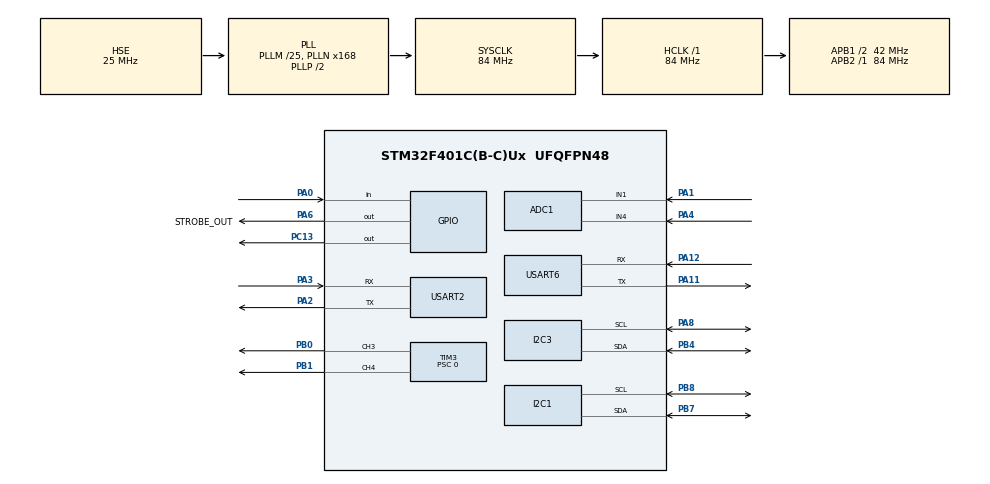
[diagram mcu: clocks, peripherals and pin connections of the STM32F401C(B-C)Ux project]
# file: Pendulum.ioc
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ADC1.Channel-0\#ChannelRegularConversion=ADC_CHANNEL_1
ADC1.Channel-1\#ChannelRegularConversion=ADC_CHANNEL_4
ADC1.ClockPrescaler=ADC_CLOCK_SYNC_PCLK_DIV8
ADC1.ContinuousConvMode=DISABLE
ADC1.DMAContinuousRequests=DISABLE
ADC1.EOCSelection=ADC_EOC_SEQ_CONV
ADC1.ExternalTrigConv=ADC_SOFTWARE_START
ADC1.NbrOfConversion=2
ADC1.NbrOfConversionFlag=1
ADC1.Rank-0\#ChannelRegularConversion=1
ADC1.Rank-1\#ChannelRegularConversion=2
ADC1.SamplingTime-0\#ChannelRegularConversion=ADC_SAMPLETIME_480CYCLES
ADC1.SamplingTime-1\#ChannelRegularConversion=ADC_SAMPLETIME_480CYCLES
ADC1.master=1
Dma.ADC1.3.Direction=DMA_PERIPH_TO_MEMORY
Dma.ADC1.3.FIFOMode=DMA_FIFOMODE_DISABLE
Dma.ADC1.3.Instance=DMA2_Stream0
Dma.ADC1.3.MemDataAlignment=DMA_MDATAALIGN_HALFWORD
Dma.ADC1.3.MemInc=DMA_MINC_ENABLE
Dma.ADC1.3.Mode=DMA_CIRCULAR
Dma.ADC1.3.PeriphDataAlignment=DMA_PDATAALIGN_HALFWORD
Dma.ADC1.3.PeriphInc=DMA_PINC_DISABLE
Dma.ADC1.3.Priority=DMA_PRIORITY_MEDIUM
Dma.I2C3_TX.0.Direction=DMA_MEMORY_TO_PERIPH
Dma.I2C3_TX.0.FIFOMode=DMA_FIFOMODE_ENABLE
Dma.I2C3_TX.0.FIFOThreshold=DMA_FIFO_THRESHOLD_FULL
Dma.I2C3_TX.0.Instance=DMA1_Stream4
Dma.I2C3_TX.0.MemBurst=DMA_MBURST_SINGLE
Dma.I2C3_TX.0.MemDataAlignment=DMA_MDATAALIGN_BYTE
Dma.I2C3_TX.0.MemInc=DMA_MINC_ENABLE
Dma.I2C3_TX.0.Mode=DMA_NORMAL
Dma.I2C3_TX.0.PeriphBurst=DMA_PBURST_SINGLE
Dma.I2C3_TX.0.PeriphDataAlignment=DMA_PDATAALIGN_BYTE
Dma.I2C3_TX.0.PeriphInc=DMA_PINC_DISABLE
Dma.I2C3_TX.0.Priority=DMA_PRIORITY_HIGH
Dma.Request0=I2C3_TX
Dma.Request1=TIM3_CH3
Dma.Request2=TIM3_CH4/UP
Dma.Request3=ADC1
Dma.TIM3_CH3.1.Direction=DMA_MEMORY_TO_PERIPH
Dma.TIM3_CH3.1.FIFOMode=DMA_FIFOMODE_ENABLE
Dma.TIM3_CH3.1.FIFOThreshold=DMA_FIFO_THRESHOLD_FULL
Dma.TIM3_CH3.1.Instance=DMA1_Stream7
Dma.TIM3_CH3.1.MemBurst=DMA_MBURST_SINGLE
Dma.TIM3_CH3.1.MemDataAlignment=DMA_MDATAALIGN_WORD
Dma.TIM3_CH3.1.MemInc=DMA_MINC_ENABLE
Dma.TIM3_CH3.1.Mode=DMA_NORMAL
Dma.TIM3_CH3.1.PeriphBurst=DMA_PBURST_SINGLE
Dma.TIM3_CH3.1.PeriphDataAlignment=DMA_PDATAALIGN_WORD
Dma.TIM3_CH3.1.PeriphInc=DMA_PINC_DISABLE
Dma.TIM3_CH3.1.Priority=DMA_PRIORITY_HIGH
Dma.TIM3_CH4/UP.2.Direction=DMA_MEMORY_TO_PERIPH
Dma.TIM3_CH4/UP.2.FIFOMode=DMA_FIFOMODE_ENABLE
Dma.TIM3_CH4/UP.2.FIFOThreshold=DMA_FIFO_THRESHOLD_FULL
Dma.TIM3_CH4/UP.2.Instance=DMA1_Stream2
Dma.TIM3_CH4/UP.2.MemBurst=DMA_MBURST_SINGLE
Dma.TIM3_CH4/UP.2.MemDataAlignment=DMA_MDATAALIGN_WORD
Dma.TIM3_CH4/UP.2.MemInc=DMA_MINC_ENABLE
Dma.TIM3_CH4/UP.2.Mode=DMA_NORMAL
Dma.TIM3_CH4/UP.2.PeriphBurst=DMA_PBURST_SINGLE
Dma.TIM3_CH4/UP.2.PeriphDataAlignment=DMA_PDATAALIGN_WORD
Dma.TIM3_CH4/UP.2.PeriphInc=DMA_PINC_DISABLE
Dma.TIM3_CH4/UP.2.Priority=DMA_PRIORITY_HIGH
I2C1.I2C_Mode=I2C_Fast
I2C3.I2C_Mode=I2C_Fast
Mcu.Family=STM32F4
Mcu.Name=STM32F401C(B-C)Ux
Mcu.Package=UFQFPN48
NVIC.DMA1_Stream2_IRQn=true\:0\:0\:false\:false\:true\:false\:true\:true
NVIC.DMA1_Stream4_IRQn=true\:0\:0\:false\:false\:true\:false\:true\:true
NVIC.DMA1_Stream7_IRQn=true\:0\:0\:false\:false\:true\:false\:true\:true
NVIC.DMA2_Stream0_IRQn=true\:0\:0\:false\:false\:true\:false\:true\:true
NVIC.I2C3_EV_IRQn=true\:0\:0\:true\:false\:true\:true\:true\:true
NVIC.PriorityGroup=NVIC_PRIORITYGROUP_4
NVIC.USART2_IRQn=true\:0\:0\:false\:false\:true\:true\:true\:true
PA0-WKUP.GPIO_PuPd=GPIO_PULLUP
PA0-WKUP.Signal=GPIO_Input
PA1.Signal=ADCx_IN1
PA11.Mode=Asynchronous
PA11.Signal=USART6_TX
PA12.Mode=Asynchronous
PA12.Signal=USART6_RX
PA2.Mode=Asynchronous
PA2.Signal=USART2_TX
PA3.Mode=Asynchronous
PA3.Signal=USART2_RX
PA4.Signal=ADCx_IN4
PA6.GPIO_Label=STROBE_OUT
PA6.GPIO_PuPd=GPIO_PULLUP
PA6.GPIO_Speed=GPIO_SPEED_FREQ_MEDIUM
PA6.Signal=GPIO_Output
PA8.GPIO_Pu=GPIO_PULLUP
PA8.Mode=I2C
PA8.Signal=I2C3_SCL
PB0.Signal=S_TIM3_CH3
PB1.Signal=S_TIM3_CH4
PB4.GPIO_Pu=GPIO_PULLUP
PB4.Mode=I2C
PB4.Signal=I2C3_SDA
PB7.GPIO_Pu=GPIO_PULLUP
PB7.Mode=I2C
PB7.Signal=I2C1_SDA
PB8.GPIO_Pu=GPIO_PULLUP
PB8.Mode=I2C
PB8.Signal=I2C1_SCL
PC13-ANTI_TAMP.GPIO_PuPd=GPIO_PULLUP
PC13-ANTI_TAMP.PinState=GPIO_PIN_SET
PC13-ANTI_TAMP.Signal=GPIO_Output
PH0\ -\ OSC_IN.Mode=HSE-External-Oscillator
PH0\ -\ OSC_IN.Signal=RCC_OSC_IN
PH1\ -\ OSC_OUT.Mode=HSE-External-Oscillator
PH1\ -\ OSC_OUT.Signal=RCC_OSC_OUT
ProjectManager.HeapSize=0x200
ProjectManager.StackSize=0x400
ProjectManager.TargetToolchain=Makefile
RCC.48MHZClocksFreq_Value=42000000
RCC.AHBFreq_Value=84000000
RCC.APB1CLKDivider=RCC_HCLK_DIV2
RCC.APB1Freq_Value=42000000
RCC.APB1TimFreq_Value=84000000
RCC.APB2Freq_Value=84000000
RCC.APB2TimFreq_Value=84000000
RCC.CortexFreq_Value=84000000
RCC.HCLKFreq_Value=84000000
RCC.HSE_VALUE=25000000
RCC.HSI_VALUE=16000000
RCC.LSE_VALUE=32768
RCC.PLLM=25
RCC.PLLN=168
RCC.PLLSourceVirtual=RCC_PLLSOURCE_HSE
RCC.SYSCLKFreq_VALUE=84000000
RCC.SYSCLKSource=RCC_SYSCLKSOURCE_PLLCLK
RCC.VCOOutputFreq_Value=168000000
SH.ADCx_IN1.0=ADC1_IN1,IN1
SH.ADCx_IN4.0=ADC1_IN4,IN4
SH.S_TIM3_CH3.0=TIM3_CH3,PWM Generation3 CH3
SH.S_TIM3_CH4.0=TIM3_CH4,PWM Generation4 CH4
TIM3.AutoReloadPreload=TIM_AUTORELOAD_PRELOAD_DISABLE
TIM3.Channel-PWM\ Generation3\ CH3=TIM_CHANNEL_3
TIM3.Channel-PWM\ Generation4\ CH4=TIM_CHANNEL_4
TIM3.OCPolarity_3=TIM_OCPOLARITY_HIGH
TIM3.Period=0
TIM3.Prescaler=0
TIM3.Pulse-PWM\ Generation3\ CH3=0
TIM3.Pulse-PWM\ Generation4\ CH4=0
USART2.VirtualMode=VM_ASYNC
USART6.VirtualMode=VM_ASYNC
board=custom

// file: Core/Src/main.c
/* USER CODE BEGIN Header */
/**
  ******************************************************************************
  * @file           : main.c
  * @brief          : Main program body
  ******************************************************************************
  * @attention
  *
  * Copyright (c) 2025 STMicroelectronics.
  * All rights reserved.
  *
  * This software is licensed under terms that can be found in the LICENSE file
  * in the root directory of this software component.
  * If no LICENSE file comes with this software, it is provided AS-IS.
  *
  ******************************************************************************
  */

/* USER CODE END Header */
#include "main.h"

/* USER CODE BEGIN Includes */

#include "app.h"

/* USER CODE END Includes */

ADC_HandleTypeDef hadc1;
DMA_HandleTypeDef hdma_adc1;

I2C_HandleTypeDef hi2c1;
I2C_HandleTypeDef hi2c3;
DMA_HandleTypeDef hdma_i2c3_tx;

TIM_HandleTypeDef htim3;
DMA_HandleTypeDef hdma_tim3_ch3;
DMA_HandleTypeDef hdma_tim3_ch4_up;

UART_HandleTypeDef huart2;
UART_HandleTypeDef huart6;

void SystemClock_Config(void);
static void MX_GPIO_Init(void);
static void MX_DMA_Init(void);
static void MX_I2C3_Init(void);
static void MX_I2C1_Init(void);
static void MX_TIM3_Init(void);
static void MX_USART2_UART_Init(void);
static void MX_ADC1_Init(void);
static void MX_USART6_UART_Init(void);

int main(void)
{

  /* MCU Configuration--------------------------------------------------------*/

  /* Reset of all peripherals, Initializes the Flash interface and the Systick. */
  HAL_Init();

  /* Configure the system clock */
  SystemClock_Config();

  /* Initialize all configured peripherals */
  MX_GPIO_Init();
  MX_DMA_Init();
  MX_I2C3_Init();
  MX_I2C1_Init();
  MX_TIM3_Init();
  MX_USART2_UART_Init();
  MX_ADC1_Init();
  MX_USART6_UART_Init();
  /* USER CODE BEGIN 2 */
  initialization();
  /* USER CODE END 2 */

  /* Infinite loop */
  /* USER CODE BEGIN WHILE */

  while (1)
  {
    exec();

    /* USER CODE END WHILE */

  }
}

void SystemClock_Config(void)
{
  RCC_OscInitTypeDef RCC_OscInitStruct = {0};
  RCC_ClkInitTypeDef RCC_ClkInitStruct = {0};

  /** Configure the main internal regulator output voltage
  */
  __HAL_RCC_PWR_CLK_ENABLE();
  __HAL_PWR_VOLTAGESCALING_CONFIG(PWR_REGULATOR_VOLTAGE_SCALE2);

  /** Initializes the RCC Oscillators according to the specified parameters
  * in the RCC_OscInitTypeDef structure.
  */
  RCC_OscInitStruct.OscillatorType = RCC_OSCILLATORTYPE_HSE;
  RCC_OscInitStruct.HSEState = RCC_HSE_ON;
  RCC_OscInitStruct.PLL.PLLState = RCC_PLL_ON;
  RCC_OscInitStruct.PLL.PLLSource = RCC_PLLSOURCE_HSE;
  RCC_OscInitStruct.PLL.PLLM = 25;
  RCC_OscInitStruct.PLL.PLLN = 168;
  RCC_OscInitStruct.PLL.PLLP = RCC_PLLP_DIV2;
  RCC_OscInitStruct.PLL.PLLQ = 4;
  if (HAL_RCC_OscConfig(&RCC_OscInitStruct) != HAL_OK)
  {
    Error_Handler();
  }

  /** Initializes the CPU, AHB and APB buses clocks
  */
  RCC_ClkInitStruct.ClockType = RCC_CLOCKTYPE_HCLK|RCC_CLOCKTYPE_SYSCLK
                              |RCC_CLOCKTYPE_PCLK1|RCC_CLOCKTYPE_PCLK2;
  RCC_ClkInitStruct.SYSCLKSource = RCC_SYSCLKSOURCE_PLLCLK;
  RCC_ClkInitStruct.AHBCLKDivider = RCC_SYSCLK_DIV1;
  RCC_ClkInitStruct.APB1CLKDivider = RCC_HCLK_DIV2;
  RCC_ClkInitStruct.APB2CLKDivider = RCC_HCLK_DIV1;

  if (HAL_RCC_ClockConfig(&RCC_ClkInitStruct, FLASH_LATENCY_2) != HAL_OK)
  {
    Error_Handler();
  }
}

static void MX_ADC1_Init(void)
{

  ADC_ChannelConfTypeDef sConfig = {0};

  /** Configure the global features of the ADC (Clock, Resolution, Data Alignment and number of conversion)
  */
  hadc1.Instance = ADC1;
  hadc1.Init.ClockPrescaler = ADC_CLOCK_SYNC_PCLK_DIV8;
  hadc1.Init.Resolution = ADC_RESOLUTION_12B;
  hadc1.Init.ScanConvMode = ENABLE;
  hadc1.Init.ContinuousConvMode = DISABLE;
  hadc1.Init.DiscontinuousConvMode = DISABLE;
  hadc1.Init.ExternalTrigConvEdge = ADC_EXTERNALTRIGCONVEDGE_NONE;
  hadc1.Init.ExternalTrigConv = ADC_SOFTWARE_START;
  hadc1.Init.DataAlign = ADC_DATAALIGN_RIGHT;
  hadc1.Init.NbrOfConversion = 2;
  hadc1.Init.DMAContinuousRequests = DISABLE;
  hadc1.Init.EOCSelection = ADC_EOC_SEQ_CONV;
  if (HAL_ADC_Init(&hadc1) != HAL_OK)
  {
    Error_Handler();
  }

  /** Configure for the selected ADC regular channel its corresponding rank in the sequencer and its sample time.
  */
  sConfig.Channel = ADC_CHANNEL_1;
  sConfig.Rank = 1;
  sConfig.SamplingTime = ADC_SAMPLETIME_480CYCLES;
  if (HAL_ADC_ConfigChannel(&hadc1, &sConfig) != HAL_OK)
  {
    Error_Handler();
  }

  /** Configure for the selected ADC regular channel its corresponding rank in the sequencer and its sample time.
  */
  sConfig.Channel = ADC_CHANNEL_4;
  sConfig.Rank = 2;
  if (HAL_ADC_ConfigChannel(&hadc1, &sConfig) != HAL_OK)
  {
    Error_Handler();
  }

}

static void MX_I2C1_Init(void)
{

  hi2c1.Instance = I2C1;
  hi2c1.Init.ClockSpeed = 400000;
  hi2c1.Init.DutyCycle = I2C_DUTYCYCLE_2;
  hi2c1.Init.OwnAddress1 = 0;
  hi2c1.Init.AddressingMode = I2C_ADDRESSINGMODE_7BIT;
  hi2c1.Init.DualAddressMode = I2C_DUALADDRESS_DISABLE;
  hi2c1.Init.OwnAddress2 = 0;
  hi2c1.Init.GeneralCallMode = I2C_GENERALCALL_DISABLE;
  hi2c1.Init.NoStretchMode = I2C_NOSTRETCH_DISABLE;
  if (HAL_I2C_Init(&hi2c1) != HAL_OK)
  {
    Error_Handler();
  }

}

static void MX_I2C3_Init(void)
{

  hi2c3.Instance = I2C3;
  hi2c3.Init.ClockSpeed = 400000;
  hi2c3.Init.DutyCycle = I2C_DUTYCYCLE_2;
  hi2c3.Init.OwnAddress1 = 0;
  hi2c3.Init.AddressingMode = I2C_ADDRESSINGMODE_7BIT;
  hi2c3.Init.DualAddressMode = I2C_DUALADDRESS_DISABLE;
  hi2c3.Init.OwnAddress2 = 0;
  hi2c3.Init.GeneralCallMode = I2C_GENERALCALL_DISABLE;
  hi2c3.Init.NoStretchMode = I2C_NOSTRETCH_DISABLE;
  if (HAL_I2C_Init(&hi2c3) != HAL_OK)
  {
    Error_Handler();
  }

}

static void MX_TIM3_Init(void)
{

  TIM_MasterConfigTypeDef sMasterConfig = {0};
  TIM_OC_InitTypeDef sConfigOC = {0};

  htim3.Instance = TIM3;
  htim3.Init.Prescaler = 0;
  htim3.Init.CounterMode = TIM_COUNTERMODE_UP;
  htim3.Init.Period = 0;
  htim3.Init.ClockDivision = TIM_CLOCKDIVISION_DIV1;
  htim3.Init.AutoReloadPreload = TIM_AUTORELOAD_PRELOAD_DISABLE;
  if (HAL_TIM_PWM_Init(&htim3) != HAL_OK)
  {
    Error_Handler();
  }
  sMasterConfig.MasterOutputTrigger = TIM_TRGO_RESET;
  sMasterConfig.MasterSlaveMode = TIM_MASTERSLAVEMODE_DISABLE;
  if (HAL_TIMEx_MasterConfigSynchronization(&htim3, &sMasterConfig) != HAL_OK)
  {
    Error_Handler();
  }
  sConfigOC.OCMode = TIM_OCMODE_PWM1;
  sConfigOC.Pulse = 0;
  sConfigOC.OCPolarity = TIM_OCPOLARITY_HIGH;
  sConfigOC.OCFastMode = TIM_OCFAST_DISABLE;
  if (HAL_TIM_PWM_ConfigChannel(&htim3, &sConfigOC, TIM_CHANNEL_3) != HAL_OK)
  {
    Error_Handler();
  }
  if (HAL_TIM_PWM_ConfigChannel(&htim3, &sConfigOC, TIM_CHANNEL_4) != HAL_OK)
  {
    Error_Handler();
  }
  HAL_TIM_MspPostInit(&htim3);

}

static void MX_USART2_UART_Init(void)
{

  huart2.Instance = USART2;
  huart2.Init.BaudRate = 115200;
  huart2.Init.WordLength = UART_WORDLENGTH_8B;
  huart2.Init.StopBits = UART_STOPBITS_1;
  huart2.Init.Parity = UART_PARITY_NONE;
  huart2.Init.Mode = UART_MODE_TX_RX;
  huart2.Init.HwFlowCtl = UART_HWCONTROL_NONE;
  huart2.Init.OverSampling = UART_OVERSAMPLING_16;
  if (HAL_UART_Init(&huart2) != HAL_OK)
  {
    Error_Handler();
  }

}

static void MX_USART6_UART_Init(void)
{

  huart6.Instance = USART6;
  huart6.Init.BaudRate = 115200;
  huart6.Init.WordLength = UART_WORDLENGTH_8B;
  huart6.Init.StopBits = UART_STOPBITS_1;
  huart6.Init.Parity = UART_PARITY_NONE;
  huart6.Init.Mode = UART_MODE_TX_RX;
  huart6.Init.HwFlowCtl = UART_HWCONTROL_NONE;
  huart6.Init.OverSampling = UART_OVERSAMPLING_16;
  if (HAL_UART_Init(&huart6) != HAL_OK)
  {
    Error_Handler();
  }

}

static void MX_DMA_Init(void)
{

  /* DMA controller clock enable */
  __HAL_RCC_DMA1_CLK_ENABLE();
  __HAL_RCC_DMA2_CLK_ENABLE();

  /* DMA interrupt init */
  /* DMA1_Stream2_IRQn interrupt configuration */
  HAL_NVIC_SetPriority(DMA1_Stream2_IRQn, 0, 0);
  HAL_NVIC_EnableIRQ(DMA1_Stream2_IRQn);
  /* DMA1_Stream4_IRQn interrupt configuration */
  HAL_NVIC_SetPriority(DMA1_Stream4_IRQn, 0, 0);
  HAL_NVIC_EnableIRQ(DMA1_Stream4_IRQn);
  /* DMA1_Stream7_IRQn interrupt configuration */
  HAL_NVIC_SetPriority(DMA1_Stream7_IRQn, 0, 0);
  HAL_NVIC_EnableIRQ(DMA1_Stream7_IRQn);
  /* DMA2_Stream0_IRQn interrupt configuration */
  HAL_NVIC_SetPriority(DMA2_Stream0_IRQn, 0, 0);
  HAL_NVIC_EnableIRQ(DMA2_Stream0_IRQn);

}

static void MX_GPIO_Init(void)
{
  GPIO_InitTypeDef GPIO_InitStruct = {0};

  /* GPIO Ports Clock Enable */
  __HAL_RCC_GPIOC_CLK_ENABLE();
  __HAL_RCC_GPIOH_CLK_ENABLE();
  __HAL_RCC_GPIOA_CLK_ENABLE();
  __HAL_RCC_GPIOB_CLK_ENABLE();

  /*Configure GPIO pin Output Level */
  HAL_GPIO_WritePin(GPIOC, GPIO_PIN_13, GPIO_PIN_SET);

  /*Configure GPIO pin Output Level */
  HAL_GPIO_WritePin(STROBE_OUT_GPIO_Port, STROBE_OUT_Pin, GPIO_PIN_RESET);

  /*Configure GPIO pin : PC13 */
  GPIO_InitStruct.Pin = GPIO_PIN_13;
  GPIO_InitStruct.Mode = GPIO_MODE_OUTPUT_PP;
  GPIO_InitStruct.Pull = GPIO_PULLUP;
  GPIO_InitStruct.Speed = GPIO_SPEED_FREQ_LOW;
  HAL_GPIO_Init(GPIOC, &GPIO_InitStruct);

  /*Configure GPIO pin : PA0 */
  GPIO_InitStruct.Pin = GPIO_PIN_0;
  GPIO_InitStruct.Mode = GPIO_MODE_INPUT;
  GPIO_InitStruct.Pull = GPIO_PULLUP;
  HAL_GPIO_Init(GPIOA, &GPIO_InitStruct);

  /*Configure GPIO pin : STROBE_OUT_Pin */
  GPIO_InitStruct.Pin = STROBE_OUT_Pin;
  GPIO_InitStruct.Mode = GPIO_MODE_OUTPUT_PP;
  GPIO_InitStruct.Pull = GPIO_PULLUP;
  GPIO_InitStruct.Speed = GPIO_SPEED_FREQ_MEDIUM;
  HAL_GPIO_Init(STROBE_OUT_GPIO_Port, &GPIO_InitStruct);

}

void Error_Handler(void)
{
  __disable_irq();
  while (1)
  {
  }
}
